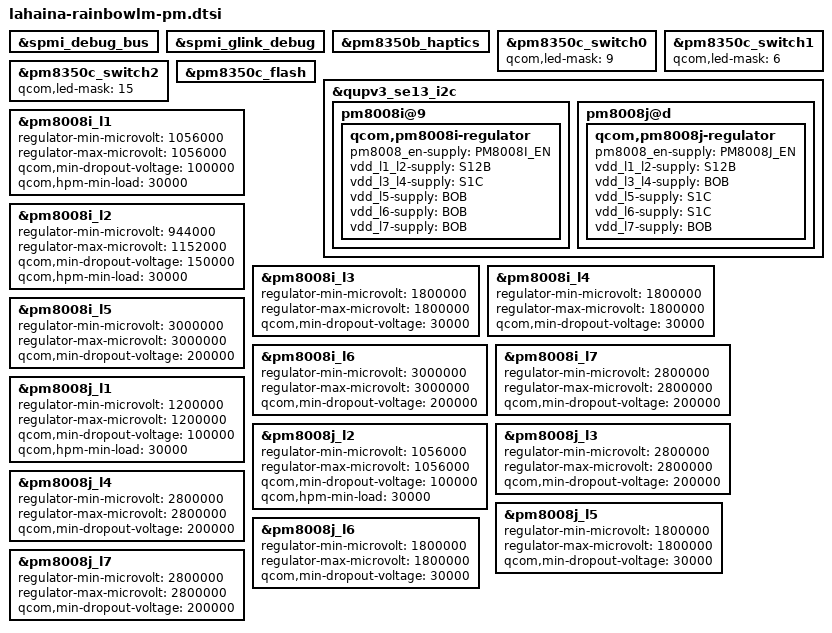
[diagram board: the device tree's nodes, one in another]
#include "../lahaina-rainbowlm_common/lahaina-rainbowlm_common-pm.dtsi"

&spmi_debug_bus {
    status = "ok";
};

&spmi_glink_debug {
    status = "ok";
};

&pm8350b_haptics {
    status = "ok";
};

&pm8350c_switch0 {
    qcom,led-mask = <9>; /* Channels 1 & 4 */
};

&pm8350c_switch1 {
    qcom,led-mask = <6>; /* Channels 2 & 3 */
};

&pm8350c_switch2 {
    qcom,led-mask = <15>; /* All Channels */
};

&pm8350c_flash {
    status = "ok";
};

&qupv3_se13_i2c {
	pm8008i@9 {
		qcom,pm8008i-regulator {
			pm8008_en-supply = <&PM8008I_EN>;
			vdd_l1_l2-supply = <&S12B>;
			vdd_l3_l4-supply = <&S1C>;
			vdd_l5-supply = <&BOB>;
			vdd_l6-supply = <&BOB>;
			vdd_l7-supply = <&BOB>;
		};
	};

	pm8008j@d {
		qcom,pm8008j-regulator {
			pm8008_en-supply = <&PM8008J_EN>;
			vdd_l1_l2-supply = <&S12B>;
			vdd_l3_l4-supply = <&BOB>;
			vdd_l5-supply = <&S1C>;
			vdd_l6-supply = <&S1C>;
			vdd_l7-supply = <&BOB>;
		};
	};
};

&pm8008i_l1 {
	regulator-min-microvolt = <1056000>;
	regulator-max-microvolt = <1056000>;
	qcom,min-dropout-voltage = <100000>;
	qcom,hpm-min-load = <30000>;
};

&pm8008i_l2 {
	regulator-min-microvolt = <944000>;
	regulator-max-microvolt = <1152000>;
	qcom,min-dropout-voltage = <150000>;
	qcom,hpm-min-load = <30000>;
};

&pm8008i_l3 {
    regulator-min-microvolt = <1800000>;
    regulator-max-microvolt = <1800000>;
    qcom,min-dropout-voltage = <30000>;
};

&pm8008i_l4 {
	regulator-min-microvolt = <1800000>;
	regulator-max-microvolt = <1800000>;
	qcom,min-dropout-voltage = <30000>;
};

&pm8008i_l5 {
	regulator-min-microvolt = <3000000>;
	regulator-max-microvolt = <3000000>;
	qcom,min-dropout-voltage = <200000>;
};

&pm8008i_l6 {
	regulator-min-microvolt = <3000000>;
	regulator-max-microvolt = <3000000>;
	qcom,min-dropout-voltage = <200000>;
};

&pm8008i_l7 {
	regulator-min-microvolt = <2800000>;
	regulator-max-microvolt = <2800000>;
	qcom,min-dropout-voltage = <200000>;
};

&pm8008j_l1 {
	regulator-min-microvolt = <1200000>;
	regulator-max-microvolt = <1200000>;
	qcom,min-dropout-voltage = <100000>;
	qcom,hpm-min-load = <30000>;
};

&pm8008j_l2 {
	regulator-min-microvolt = <1056000>;
	regulator-max-microvolt = <1056000>;
	qcom,min-dropout-voltage = <100000>;
	qcom,hpm-min-load = <30000>;
};

&pm8008j_l3 {
	regulator-min-microvolt = <2800000>;
	regulator-max-microvolt = <2800000>;
	qcom,min-dropout-voltage = <200000>;
};

&pm8008j_l4 {
	regulator-min-microvolt = <2800000>;
	regulator-max-microvolt = <2800000>;
	qcom,min-dropout-voltage = <200000>;
};

&pm8008j_l5 {
    regulator-min-microvolt = <1800000>;
    regulator-max-microvolt = <1800000>;
    qcom,min-dropout-voltage = <30000>;
};

&pm8008j_l6 {
    regulator-min-microvolt = <1800000>;
    regulator-max-microvolt = <1800000>;
    qcom,min-dropout-voltage = <30000>;
};

&pm8008j_l7 {
	regulator-min-microvolt = <2800000>;
	regulator-max-microvolt = <2800000>;
	qcom,min-dropout-voltage = <200000>;
};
